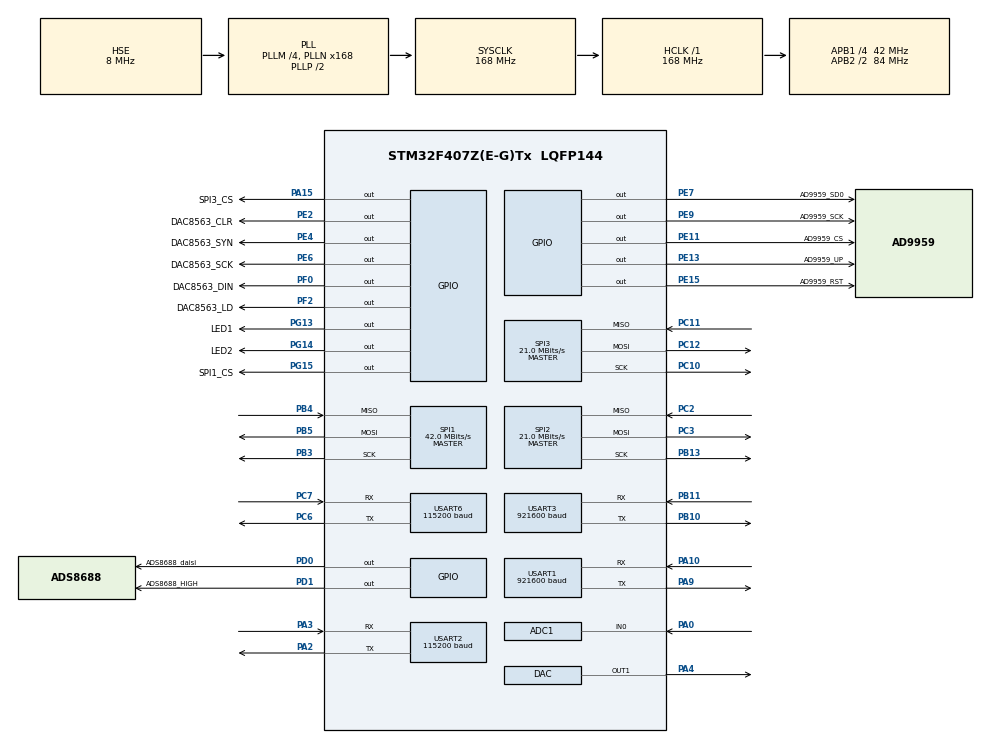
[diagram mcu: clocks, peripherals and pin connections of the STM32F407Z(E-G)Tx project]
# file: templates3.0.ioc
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PH0-OSC_IN.Signal=RCC_OSC_IN
SPI3.Direction=SPI_DIRECTION_2LINES
SPI3.VirtualType=VM_MASTER
SPI1.VirtualType=VM_MASTER
SPI2.VirtualType=VM_MASTER
PB10.Mode=Asynchronous
PC12.Signal=SPI3_MOSI
Dma.SPI3_RX.2.Direction=DMA_PERIPH_TO_MEMORY
PB13.Signal=SPI2_SCK
PG13.Signal=GPIO_Output
PE6.GPIO_Label=DAC8563_SCK
RCC.SYSCLKSource=RCC_SYSCLKSOURCE_PLLCLK
USART3.BaudRate=921600
PG15.GPIO_Label=SPI1_CS
SPI1.Direction=SPI_DIRECTION_2LINES
RCC.APB2TimFreq_Value=168000000
Dma.ADC1.0.Direction=DMA_PERIPH_TO_MEMORY
PC7.Signal=USART6_RX
SPI1.CalculateBaudRate=42.0 MBits/s
PC3.Signal=SPI2_MOSI
PD0.Signal=GPIO_Output
Dma.ADC1.0.MemDataAlignment=DMA_MDATAALIGN_HALFWORD
PB3.Mode=Full_Duplex_Master
PD1.GPIO_Label=ADS8688_HIGH
DAC.DAC_Trigger=DAC_TRIGGER_T6_TRGO
PD1.GPIO_Speed=GPIO_SPEED_FREQ_MEDIUM
PE9.Signal=GPIO_Output
Dma.ADC1.0.PeriphInc=DMA_PINC_DISABLE
SPI1.DataSize=SPI_DATASIZE_8BIT
PE4.GPIO_Label=DAC8563_SYN
SPI2.CalculateBaudRate=21.0 MBits/s
PE2.Signal=GPIO_Output
Dma.DAC1.1.Priority=DMA_PRIORITY_LOW
Mcu.Package=LQFP144
SPI2.Mode=SPI_MODE_MASTER
SPI3.Mode=SPI_MODE_MASTER
PA10.Signal=USART1_RX
PC11.Mode=Full_Duplex_Master
Dma.SPI3_RX.2.PeriphInc=DMA_PINC_DISABLE
RCC.APB2CLKDivider=RCC_HCLK_DIV2
RCC.APB1TimFreq_Value=84000000
Dma.ADC1.0.FIFOMode=DMA_FIFOMODE_DISABLE
PB13.Mode=Full_Duplex_Master
VP_TIM14_VS_ClockSourceINT.Mode=Enable_Timer
PE6.GPIO_Speed=GPIO_SPEED_FREQ_VERY_HIGH
Dma.SPI3_TX.3.Mode=DMA_NORMAL
Dma.ADC1.0.Instance=DMA2_Stream0
PE11.GPIO_Speed=GPIO_SPEED_FREQ_VERY_HIGH
PC6.Signal=USART6_TX
PC2.Signal=SPI2_MISO
PD1.Signal=GPIO_Output
PD1.GPIO_PuPd=GPIO_PULLUP
RCC.APB1CLKDivider=RCC_HCLK_DIV4
PG13.GPIO_Label=LED1
USART2.BaudRate=115200
PA0-WKUP.Signal=ADCx_IN0
PD0.GPIO_Speed=GPIO_SPEED_FREQ_MEDIUM
PA3.Mode=Asynchronous
PB11.Mode=Asynchronous
Dma.DAC1.1.Mode=DMA_CIRCULAR
PC6.Mode=Asynchronous
Dma.ADC1.0.Priority=DMA_PRIORITY_LOW
PA9.Signal=USART1_TX
PE9.GPIO_Label=AD9959_SCK
PB10.Signal=USART3_TX
PC12.Mode=Full_Duplex_Master
Dma.SPI3_TX.3.FIFOMode=DMA_FIFOMODE_DISABLE
NVIC.TIM3_IRQn=true\:3\:0\:true\:false\:true\:true\:false
VP_TIM13_VS_ClockSourceINT.Mode=Enable_Timer
Dma.SPI3_TX.3.Direction=DMA_MEMORY_TO_PERIPH
PE7.GPIO_Speed=GPIO_SPEED_FREQ_VERY_HIGH
PE15.Signal=GPIO_Output
SPI1.Mode=SPI_MODE_MASTER
ADC1.DMAContinuousRequests=ENABLE
PG14.GPIO_Label=LED2
Dma.DAC1.1.FIFOMode=DMA_FIFOMODE_DISABLE
TIM14.Prescaler=0
ADC1.SamplingTime-1\#ChannelRegularConversion=ADC_SAMPLETIME_3CYCLES
PA4.Signal=COMP_DAC1_group
PB5.Signal=SPI1_MOSI
ADC1.master=1
PE13.GPIO_Label=AD9959_UP
Dma.DAC1.1.Instance=DMA1_Stream5
USART1.VirtualMode=VM_ASYNC
ADC1.Rank-1\#ChannelRegularConversion=1
PD1.PinState=GPIO_PIN_SET
ProjectManager.HeapSize=0x200
NVIC.PriorityGroup=NVIC_PRIORITYGROUP_4
PE15.GPIO_Speed=GPIO_SPEED_FREQ_VERY_HIGH
PF0.GPIO_Label=DAC8563_DIN
Dma.SPI3_TX.3.Instance=DMA1_Stream7
Mcu.Family=STM32F4
NVIC.USART3_IRQn=true\:0\:0\:false\:false\:true\:true\:true
PC3.Mode=Full_Duplex_Master
RCC.CortexFreq_Value=168000000
Dma.SPI3_TX.3.MemDataAlignment=DMA_MDATAALIGN_HALFWORD
ADC1.ContinuousConvMode=ENABLE
PE11.GPIO_Label=AD9959_CS
USART1.BaudRate=921600
Dma.SPI3_RX.2.Instance=DMA1_Stream0
PC10.Signal=SPI3_SCK
Dma.DAC1.1.PeriphInc=DMA_PINC_DISABLE
PE2.GPIO_Speed=GPIO_SPEED_FREQ_VERY_HIGH
PD0.GPIO_Label=ADS8688_daisi
PE9.GPIO_Speed=GPIO_SPEED_FREQ_VERY_HIGH
PB11.Signal=USART3_RX
PF2.GPIO_Speed=GPIO_SPEED_FREQ_VERY_HIGH
PG15.Signal=GPIO_Output
Dma.SPI3_RX.2.PeriphDataAlignment=DMA_PDATAALIGN_HALFWORD
ProjectManager.StackSize=0x400
VP_TIM7_VS_ClockSourceINT.Mode=Enable_Timer
PA15.GPIO_Label=SPI3_CS
PG14.PinState=GPIO_PIN_SET
SPI1.CLKPolarity=SPI_POLARITY_LOW
RCC.HCLKFreq_Value=168000000
TIM3.Period=5249
TIM7.Period=9999
RCC.AHBFreq_Value=168000000
PH0-OSC_IN.Mode=HSE-External-Oscillator
SPI3.DataSize=SPI_DATASIZE_16BIT
RCC.HSE_VALUE=8000000
Dma.SPI3_TX.3.PeriphInc=DMA_PINC_DISABLE
Dma.SPI3_TX.3.Priority=DMA_PRIORITY_VERY_HIGH
PB4.Mode=Full_Duplex_Master
PE13.Signal=GPIO_Output
PD0.PinState=GPIO_PIN_SET
PE4.GPIO_Speed=GPIO_SPEED_FREQ_VERY_HIGH
PB5.Mode=Full_Duplex_Master
Dma.DAC1.1.PeriphDataAlignment=DMA_PDATAALIGN_HALFWORD
SH.ADCx_IN0.0=ADC1_IN0,IN0
TIM6.Period=9
PE4.Signal=GPIO_Output
Dma.SPI3_RX.2.FIFOMode=DMA_FIFOMODE_DISABLE
NVIC.DMA1_Stream7_IRQn=true\:4\:0\:true\:false\:true\:true\:true
Dma.DAC1.1.Direction=DMA_MEMORY_TO_PERIPH
PH1-OSC_OUT.Mode=HSE-External-Oscillator
USART2.VirtualMode=VM_ASYNC
USART6.VirtualMode=VM_ASYNC
PA15.Signal=GPIO_Output
USART6.BaudRate=115200
Dma.SPI3_RX.2.Priority=DMA_PRIORITY_VERY_HIGH
Dma.Request2=SPI3_RX
Dma.Request1=DAC1
Dma.Request3=SPI3_TX
NVIC.DMA1_Stream0_IRQn=true\:4\:0\:true\:false\:true\:true\:true
PG13.GPIO_Speed=GPIO_SPEED_FREQ_HIGH
SPI2.Direction=SPI_DIRECTION_2LINES
PF0.Signal=GPIO_Output
PE7.Signal=GPIO_Output
SPI3.CRCCalculation=SPI_CRCCALCULATION_DISABLE
Dma.Request0=ADC1
SPI1.BaudRatePrescaler=SPI_BAUDRATEPRESCALER_2
Dma.DAC1.1.MemDataAlignment=DMA_MDATAALIGN_HALFWORD
PE2.GPIO_Label=DAC8563_CLR
NVIC.TIM7_IRQn=true\:2\:0\:true\:false\:true\:true\:false
VP_TIM3_VS_ClockSourceINT.Mode=Internal
PB4.Signal=SPI1_MISO
PA3.Signal=USART2_RX
Dma.SPI3_TX.3.MemInc=DMA_MINC_ENABLE
RCC.PLLSourceVirtual=RCC_PLLSOURCE_HSE
SH.COMP_DAC1_group.0=DAC_OUT1,DAC_OUT1
PA10.Mode=Asynchronous
PC11.Signal=SPI3_MISO
TIM6.Prescaler=83
PC10.Mode=Full_Duplex_Master
VP_TIM6_VS_ClockSourceINT.Mode=Enable_Timer
PC2.Mode=Full_Duplex_Master
NVIC.USART2_IRQn=true\:0\:0\:false\:false\:true\:true\:true
NVIC.USART6_IRQn=true\:1\:0\:true\:false\:true\:true\:true
PF0.GPIO_Speed=GPIO_SPEED_FREQ_VERY_HIGH
Dma.DAC1.1.MemInc=DMA_MINC_ENABLE
Dma.ADC1.0.PeriphDataAlignment=DMA_PDATAALIGN_HALFWORD
PA9.Mode=Asynchronous
PE15.GPIO_Label=AD9959_RST
ProjectManager.TargetToolchain=STM32CubeIDE
Dma.ADC1.0.Mode=DMA_CIRCULAR
ADC1.Channel-1\#ChannelRegularConversion=ADC_CHANNEL_0
PF2.Signal=GPIO_Output
PE11.Signal=GPIO_Output
RCC.LSE_VALUE=32768
PG14.Signal=GPIO_Output
TIM7.Prescaler=8399
board=custom
SPI3.CLKPhase=SPI_PHASE_2EDGE
RCC.VCOOutputFreq_Value=336000000
PA15.PinState=GPIO_PIN_SET
RCC.APB2Freq_Value=84000000
SPI3.CalculateBaudRate=21.0 MBits/s
VP_TIM2_VS_ClockSourceINT.Mode=Internal
SPI3.BaudRatePrescaler=SPI_BAUDRATEPRESCALER_2
Dma.SPI3_TX.3.PeriphDataAlignment=DMA_PDATAALIGN_HALFWORD
TIM6.TIM_MasterOutputTrigger=TIM_TRGO_UPDATE
PH1-OSC_OUT.Signal=RCC_OSC_OUT
PE6.Signal=GPIO_Output
Dma.SPI3_RX.2.Mode=DMA_NORMAL
Mcu.Name=STM32F407Z(E-G)Tx
PE7.GPIO_Label=AD9959_SD0
PA2.Signal=USART2_TX
RCC.48MHZClocksFreq_Value=84000000
PB3.Signal=SPI1_SCK
RCC.SYSCLKFreq_VALUE=168000000
USART3.VirtualMode=VM_ASYNC
Dma.SPI3_RX.2.MemInc=DMA_MINC_ENABLE
PA15.GPIO_Speed=GPIO_SPEED_FREQ_VERY_HIGH
Dma.ADC1.0.MemInc=DMA_MINC_ENABLE
RCC.HSI_VALUE=16000000
ADC1.NbrOfConversionFlag=1
RCC.PLLM=4
RCC.PLLN=168
PE13.GPIO_Speed=GPIO_SPEED_FREQ_VERY_HIGH
PA2.Mode=Asynchronous
PC7.Mode=Asynchronous
Dma.SPI3_RX.2.MemDataAlignment=DMA_MDATAALIGN_HALFWORD
RCC.APB1Freq_Value=42000000
PG14.GPIO_Speed=GPIO_SPEED_FREQ_HIGH
PF2.GPIO_Label=DAC8563_LD

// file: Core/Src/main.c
/* USER CODE BEGIN Header */
/**
  ******************************************************************************
  * @file           : main.c
  * @brief          : Main program body
  ******************************************************************************
  * @attention
  *
  * <h2><center>&copy; Copyright (c) 2021 STMicroelectronics.
  * All rights reserved.</center></h2>
  *
  * This software component is licensed by ST under BSD 3-Clause license,
  * the "License"; You may not use this file except in compliance with the
  * License. You may obtain a copy of the License at:
  *                        opensource.org/licenses/BSD-3-Clause
  *
  ******************************************************************************
  */
/* USER CODE END Header */
#include "main.h"

ADC_HandleTypeDef hadc1;
DMA_HandleTypeDef hdma_adc1;

DAC_HandleTypeDef hdac;
DMA_HandleTypeDef hdma_dac1;

SPI_HandleTypeDef hspi1;
SPI_HandleTypeDef hspi2;
SPI_HandleTypeDef hspi3;
DMA_HandleTypeDef hdma_spi3_rx;
DMA_HandleTypeDef hdma_spi3_tx;

TIM_HandleTypeDef htim2;
TIM_HandleTypeDef htim3;
TIM_HandleTypeDef htim6;
TIM_HandleTypeDef htim7;
TIM_HandleTypeDef htim13;
TIM_HandleTypeDef htim14;

UART_HandleTypeDef huart1;
UART_HandleTypeDef huart2;
UART_HandleTypeDef huart3;
UART_HandleTypeDef huart6;

void SystemClock_Config(void);
static void MX_GPIO_Init(void);
static void MX_DMA_Init(void);
static void MX_SPI3_Init(void);
static void MX_TIM7_Init(void);
static void MX_USART1_UART_Init(void);
static void MX_USART2_UART_Init(void);
static void MX_USART3_UART_Init(void);
static void MX_USART6_UART_Init(void);
static void MX_SPI1_Init(void);
static void MX_TIM3_Init(void);
static void MX_ADC1_Init(void);
static void MX_DAC_Init(void);
static void MX_TIM6_Init(void);
static void MX_TIM2_Init(void);
static void MX_TIM14_Init(void);
static void MX_SPI2_Init(void);
static void MX_TIM13_Init(void);

int main(void)
{

  /* MCU Configuration--------------------------------------------------------*/

  /* Reset of all peripherals, Initializes the Flash interface and the Systick. */
  HAL_Init();

  /* Configure the system clock */
  SystemClock_Config();

  /* Initialize all configured peripherals */
  MX_GPIO_Init();
  MX_DMA_Init();
  MX_SPI3_Init();
  MX_TIM7_Init();
  MX_USART1_UART_Init();
  MX_USART2_UART_Init();
  MX_USART3_UART_Init();
  MX_USART6_UART_Init();
  MX_SPI1_Init();
  MX_TIM3_Init();
  MX_ADC1_Init();
  MX_DAC_Init();
  MX_TIM6_Init();
  MX_TIM2_Init();
  MX_TIM14_Init();
  MX_SPI2_Init();
  MX_TIM13_Init();
  /* USER CODE BEGIN 2 */

  init_start();

  /* USER CODE END 2 */

  /* Infinite loop */
  /* USER CODE BEGIN WHILE */
  while (1)
  {
	  while_do();
    /* USER CODE END WHILE */

  }
}

void SystemClock_Config(void)
{
  RCC_OscInitTypeDef RCC_OscInitStruct = {0};
  RCC_ClkInitTypeDef RCC_ClkInitStruct = {0};

  /** Configure the main internal regulator output voltage
  */
  __HAL_RCC_PWR_CLK_ENABLE();
  __HAL_PWR_VOLTAGESCALING_CONFIG(PWR_REGULATOR_VOLTAGE_SCALE1);
  /** Initializes the RCC Oscillators according to the specified parameters
  * in the RCC_OscInitTypeDef structure.
  */
  RCC_OscInitStruct.OscillatorType = RCC_OSCILLATORTYPE_HSE;
  RCC_OscInitStruct.HSEState = RCC_HSE_ON;
  RCC_OscInitStruct.PLL.PLLState = RCC_PLL_ON;
  RCC_OscInitStruct.PLL.PLLSource = RCC_PLLSOURCE_HSE;
  RCC_OscInitStruct.PLL.PLLM = 4;
  RCC_OscInitStruct.PLL.PLLN = 168;
  RCC_OscInitStruct.PLL.PLLP = RCC_PLLP_DIV2;
  RCC_OscInitStruct.PLL.PLLQ = 4;
  if (HAL_RCC_OscConfig(&RCC_OscInitStruct) != HAL_OK)
  {
    Error_Handler();
  }
  /** Initializes the CPU, AHB and APB buses clocks
  */
  RCC_ClkInitStruct.ClockType = RCC_CLOCKTYPE_HCLK|RCC_CLOCKTYPE_SYSCLK
                              |RCC_CLOCKTYPE_PCLK1|RCC_CLOCKTYPE_PCLK2;
  RCC_ClkInitStruct.SYSCLKSource = RCC_SYSCLKSOURCE_PLLCLK;
  RCC_ClkInitStruct.AHBCLKDivider = RCC_SYSCLK_DIV1;
  RCC_ClkInitStruct.APB1CLKDivider = RCC_HCLK_DIV4;
  RCC_ClkInitStruct.APB2CLKDivider = RCC_HCLK_DIV2;

  if (HAL_RCC_ClockConfig(&RCC_ClkInitStruct, FLASH_LATENCY_5) != HAL_OK)
  {
    Error_Handler();
  }
}

static void MX_ADC1_Init(void)
{

  ADC_ChannelConfTypeDef sConfig = {0};

  /** Configure the global features of the ADC (Clock, Resolution, Data Alignment and number of conversion)
  */
  hadc1.Instance = ADC1;
  hadc1.Init.ClockPrescaler = ADC_CLOCK_SYNC_PCLK_DIV4;
  hadc1.Init.Resolution = ADC_RESOLUTION_12B;
  hadc1.Init.ScanConvMode = DISABLE;
  hadc1.Init.ContinuousConvMode = ENABLE;
  hadc1.Init.DiscontinuousConvMode = DISABLE;
  hadc1.Init.ExternalTrigConvEdge = ADC_EXTERNALTRIGCONVEDGE_NONE;
  hadc1.Init.ExternalTrigConv = ADC_SOFTWARE_START;
  hadc1.Init.DataAlign = ADC_DATAALIGN_RIGHT;
  hadc1.Init.NbrOfConversion = 1;
  hadc1.Init.DMAContinuousRequests = ENABLE;
  hadc1.Init.EOCSelection = ADC_EOC_SINGLE_CONV;
  if (HAL_ADC_Init(&hadc1) != HAL_OK)
  {
    Error_Handler();
  }
  /** Configure for the selected ADC regular channel its corresponding rank in the sequencer and its sample time.
  */
  sConfig.Channel = ADC_CHANNEL_0;
  sConfig.Rank = 1;
  sConfig.SamplingTime = ADC_SAMPLETIME_3CYCLES;
  if (HAL_ADC_ConfigChannel(&hadc1, &sConfig) != HAL_OK)
  {
    Error_Handler();
  }

}

static void MX_DAC_Init(void)
{

  DAC_ChannelConfTypeDef sConfig = {0};

  /** DAC Initialization
  */
  hdac.Instance = DAC;
  if (HAL_DAC_Init(&hdac) != HAL_OK)
  {
    Error_Handler();
  }
  /** DAC channel OUT1 config
  */
  sConfig.DAC_Trigger = DAC_TRIGGER_T6_TRGO;
  sConfig.DAC_OutputBuffer = DAC_OUTPUTBUFFER_ENABLE;
  if (HAL_DAC_ConfigChannel(&hdac, &sConfig, DAC_CHANNEL_1) != HAL_OK)
  {
    Error_Handler();
  }

}

static void MX_SPI1_Init(void)
{

  /* SPI1 parameter configuration*/
  hspi1.Instance = SPI1;
  hspi1.Init.Mode = SPI_MODE_MASTER;
  hspi1.Init.Direction = SPI_DIRECTION_2LINES;
  hspi1.Init.DataSize = SPI_DATASIZE_8BIT;
  hspi1.Init.CLKPolarity = SPI_POLARITY_LOW;
  hspi1.Init.CLKPhase = SPI_PHASE_1EDGE;
  hspi1.Init.NSS = SPI_NSS_SOFT;
  hspi1.Init.BaudRatePrescaler = SPI_BAUDRATEPRESCALER_2;
  hspi1.Init.FirstBit = SPI_FIRSTBIT_MSB;
  hspi1.Init.TIMode = SPI_TIMODE_DISABLE;
  hspi1.Init.CRCCalculation = SPI_CRCCALCULATION_DISABLE;
  hspi1.Init.CRCPolynomial = 10;
  if (HAL_SPI_Init(&hspi1) != HAL_OK)
  {
    Error_Handler();
  }

}

static void MX_SPI2_Init(void)
{

  /* SPI2 parameter configuration*/
  hspi2.Instance = SPI2;
  hspi2.Init.Mode = SPI_MODE_MASTER;
  hspi2.Init.Direction = SPI_DIRECTION_2LINES;
  hspi2.Init.DataSize = SPI_DATASIZE_8BIT;
  hspi2.Init.CLKPolarity = SPI_POLARITY_LOW;
  hspi2.Init.CLKPhase = SPI_PHASE_1EDGE;
  hspi2.Init.NSS = SPI_NSS_SOFT;
  hspi2.Init.BaudRatePrescaler = SPI_BAUDRATEPRESCALER_2;
  hspi2.Init.FirstBit = SPI_FIRSTBIT_MSB;
  hspi2.Init.TIMode = SPI_TIMODE_DISABLE;
  hspi2.Init.CRCCalculation = SPI_CRCCALCULATION_DISABLE;
  hspi2.Init.CRCPolynomial = 10;
  if (HAL_SPI_Init(&hspi2) != HAL_OK)
  {
    Error_Handler();
  }

}

static void MX_SPI3_Init(void)
{

  /* SPI3 parameter configuration*/
  hspi3.Instance = SPI3;
  hspi3.Init.Mode = SPI_MODE_MASTER;
  hspi3.Init.Direction = SPI_DIRECTION_2LINES;
  hspi3.Init.DataSize = SPI_DATASIZE_16BIT;
  hspi3.Init.CLKPolarity = SPI_POLARITY_LOW;
  hspi3.Init.CLKPhase = SPI_PHASE_2EDGE;
  hspi3.Init.NSS = SPI_NSS_SOFT;
  hspi3.Init.BaudRatePrescaler = SPI_BAUDRATEPRESCALER_2;
  hspi3.Init.FirstBit = SPI_FIRSTBIT_MSB;
  hspi3.Init.TIMode = SPI_TIMODE_DISABLE;
  hspi3.Init.CRCCalculation = SPI_CRCCALCULATION_DISABLE;
  hspi3.Init.CRCPolynomial = 10;
  if (HAL_SPI_Init(&hspi3) != HAL_OK)
  {
    Error_Handler();
  }

}

static void MX_TIM2_Init(void)
{

  TIM_ClockConfigTypeDef sClockSourceConfig = {0};
  TIM_MasterConfigTypeDef sMasterConfig = {0};

  htim2.Instance = TIM2;
  htim2.Init.Prescaler = 0;
  htim2.Init.CounterMode = TIM_COUNTERMODE_UP;
  htim2.Init.Period = 4294967295;
  htim2.Init.ClockDivision = TIM_CLOCKDIVISION_DIV1;
  htim2.Init.AutoReloadPreload = TIM_AUTORELOAD_PRELOAD_DISABLE;
  if (HAL_TIM_Base_Init(&htim2) != HAL_OK)
  {
    Error_Handler();
  }
  sClockSourceConfig.ClockSource = TIM_CLOCKSOURCE_INTERNAL;
  if (HAL_TIM_ConfigClockSource(&htim2, &sClockSourceConfig) != HAL_OK)
  {
    Error_Handler();
  }
  sMasterConfig.MasterOutputTrigger = TIM_TRGO_RESET;
  sMasterConfig.MasterSlaveMode = TIM_MASTERSLAVEMODE_DISABLE;
  if (HAL_TIMEx_MasterConfigSynchronization(&htim2, &sMasterConfig) != HAL_OK)
  {
    Error_Handler();
  }

}

static void MX_TIM3_Init(void)
{

  TIM_ClockConfigTypeDef sClockSourceConfig = {0};
  TIM_MasterConfigTypeDef sMasterConfig = {0};

  htim3.Instance = TIM3;
  htim3.Init.Prescaler = 0;
  htim3.Init.CounterMode = TIM_COUNTERMODE_UP;
  htim3.Init.Period = 5249;
  htim3.Init.ClockDivision = TIM_CLOCKDIVISION_DIV1;
  htim3.Init.AutoReloadPreload = TIM_AUTORELOAD_PRELOAD_DISABLE;
  if (HAL_TIM_Base_Init(&htim3) != HAL_OK)
  {
    Error_Handler();
  }
  sClockSourceConfig.ClockSource = TIM_CLOCKSOURCE_INTERNAL;
  if (HAL_TIM_ConfigClockSource(&htim3, &sClockSourceConfig) != HAL_OK)
  {
    Error_Handler();
  }
  sMasterConfig.MasterOutputTrigger = TIM_TRGO_RESET;
  sMasterConfig.MasterSlaveMode = TIM_MASTERSLAVEMODE_DISABLE;
  if (HAL_TIMEx_MasterConfigSynchronization(&htim3, &sMasterConfig) != HAL_OK)
  {
    Error_Handler();
  }

}

static void MX_TIM6_Init(void)
{

  TIM_MasterConfigTypeDef sMasterConfig = {0};

  htim6.Instance = TIM6;
  htim6.Init.Prescaler = 83;
  htim6.Init.CounterMode = TIM_COUNTERMODE_UP;
  htim6.Init.Period = 9;
  htim6.Init.AutoReloadPreload = TIM_AUTORELOAD_PRELOAD_DISABLE;
  if (HAL_TIM_Base_Init(&htim6) != HAL_OK)
  {
    Error_Handler();
  }
  sMasterConfig.MasterOutputTrigger = TIM_TRGO_UPDATE;
  sMasterConfig.MasterSlaveMode = TIM_MASTERSLAVEMODE_DISABLE;
  if (HAL_TIMEx_MasterConfigSynchronization(&htim6, &sMasterConfig) != HAL_OK)
  {
    Error_Handler();
  }

}

static void MX_TIM7_Init(void)
{

  TIM_MasterConfigTypeDef sMasterConfig = {0};

  htim7.Instance = TIM7;
  htim7.Init.Prescaler = 8399;
  htim7.Init.CounterMode = TIM_COUNTERMODE_UP;
  htim7.Init.Period = 9999;
  htim7.Init.AutoReloadPreload = TIM_AUTORELOAD_PRELOAD_DISABLE;
  if (HAL_TIM_Base_Init(&htim7) != HAL_OK)
  {
    Error_Handler();
  }
  sMasterConfig.MasterOutputTrigger = TIM_TRGO_RESET;
  sMasterConfig.MasterSlaveMode = TIM_MASTERSLAVEMODE_DISABLE;
  if (HAL_TIMEx_MasterConfigSynchronization(&htim7, &sMasterConfig) != HAL_OK)
  {
    Error_Handler();
  }

}

static void MX_TIM13_Init(void)
{

  htim13.Instance = TIM13;
  htim13.Init.Prescaler = 0;
  htim13.Init.CounterMode = TIM_COUNTERMODE_UP;
  htim13.Init.Period = 65535;
  htim13.Init.ClockDivision = TIM_CLOCKDIVISION_DIV1;
  htim13.Init.AutoReloadPreload = TIM_AUTORELOAD_PRELOAD_DISABLE;
  if (HAL_TIM_Base_Init(&htim13) != HAL_OK)
  {
    Error_Handler();
  }

}

static void MX_TIM14_Init(void)
{

  htim14.Instance = TIM14;
  htim14.Init.Prescaler = 0;
  htim14.Init.CounterMode = TIM_COUNTERMODE_UP;
  htim14.Init.Period = 65535;
  htim14.Init.ClockDivision = TIM_CLOCKDIVISION_DIV1;
  htim14.Init.AutoReloadPreload = TIM_AUTORELOAD_PRELOAD_DISABLE;
  if (HAL_TIM_Base_Init(&htim14) != HAL_OK)
  {
    Error_Handler();
  }

}

static void MX_USART1_UART_Init(void)
{

  huart1.Instance = USART1;
  huart1.Init.BaudRate = 921600;
  huart1.Init.WordLength = UART_WORDLENGTH_8B;
  huart1.Init.StopBits = UART_STOPBITS_1;
  huart1.Init.Parity = UART_PARITY_NONE;
  huart1.Init.Mode = UART_MODE_TX_RX;
  huart1.Init.HwFlowCtl = UART_HWCONTROL_NONE;
  huart1.Init.OverSampling = UART_OVERSAMPLING_16;
  if (HAL_UART_Init(&huart1) != HAL_OK)
  {
    Error_Handler();
  }

}

static void MX_USART2_UART_Init(void)
{

  huart2.Instance = USART2;
  huart2.Init.BaudRate = 115200;
  huart2.Init.WordLength = UART_WORDLENGTH_8B;
  huart2.Init.StopBits = UART_STOPBITS_1;
  huart2.Init.Parity = UART_PARITY_NONE;
  huart2.Init.Mode = UART_MODE_TX_RX;
  huart2.Init.HwFlowCtl = UART_HWCONTROL_NONE;
  huart2.Init.OverSampling = UART_OVERSAMPLING_16;
  if (HAL_UART_Init(&huart2) != HAL_OK)
  {
    Error_Handler();
  }

}

static void MX_USART3_UART_Init(void)
{

  huart3.Instance = USART3;
  huart3.Init.BaudRate = 921600;
  huart3.Init.WordLength = UART_WORDLENGTH_8B;
  huart3.Init.StopBits = UART_STOPBITS_1;
  huart3.Init.Parity = UART_PARITY_NONE;
  huart3.Init.Mode = UART_MODE_TX_RX;
  huart3.Init.HwFlowCtl = UART_HWCONTROL_NONE;
  huart3.Init.OverSampling = UART_OVERSAMPLING_16;
  if (HAL_UART_Init(&huart3) != HAL_OK)
  {
    Error_Handler();
  }

}

static void MX_USART6_UART_Init(void)
{

  huart6.Instance = USART6;
  huart6.Init.BaudRate = 115200;
  huart6.Init.WordLength = UART_WORDLENGTH_8B;
  huart6.Init.StopBits = UART_STOPBITS_1;
  huart6.Init.Parity = UART_PARITY_NONE;
  huart6.Init.Mode = UART_MODE_TX_RX;
  huart6.Init.HwFlowCtl = UART_HWCONTROL_NONE;
  huart6.Init.OverSampling = UART_OVERSAMPLING_16;
  if (HAL_UART_Init(&huart6) != HAL_OK)
  {
    Error_Handler();
  }

}

static void MX_DMA_Init(void)
{

  /* DMA controller clock enable */
  __HAL_RCC_DMA2_CLK_ENABLE();
  __HAL_RCC_DMA1_CLK_ENABLE();

  /* DMA interrupt init */
  /* DMA1_Stream0_IRQn interrupt configuration */
  HAL_NVIC_SetPriority(DMA1_Stream0_IRQn, 4, 0);
  HAL_NVIC_EnableIRQ(DMA1_Stream0_IRQn);
  /* DMA1_Stream7_IRQn interrupt configuration */
  HAL_NVIC_SetPriority(DMA1_Stream7_IRQn, 4, 0);
  HAL_NVIC_EnableIRQ(DMA1_Stream7_IRQn);

}

static void MX_GPIO_Init(void)
{
  GPIO_InitTypeDef GPIO_InitStruct = {0};

  /* GPIO Ports Clock Enable */
  __HAL_RCC_GPIOE_CLK_ENABLE();
  __HAL_RCC_GPIOF_CLK_ENABLE();
  __HAL_RCC_GPIOH_CLK_ENABLE();
  __HAL_RCC_GPIOC_CLK_ENABLE();
  __HAL_RCC_GPIOA_CLK_ENABLE();
  __HAL_RCC_GPIOB_CLK_ENABLE();
  __HAL_RCC_GPIOD_CLK_ENABLE();
  __HAL_RCC_GPIOG_CLK_ENABLE();

  /*Configure GPIO pin Output Level */
  HAL_GPIO_WritePin(GPIOE, DAC8563_CLR_Pin|DAC8563_SYN_Pin|DAC8563_SCK_Pin|AD9959_SD0_Pin
                          |AD9959_SCK_Pin|AD9959_CS_Pin|AD9959_UP_Pin|AD9959_RST_Pin, GPIO_PIN_RESET);

  /*Configure GPIO pin Output Level */
  HAL_GPIO_WritePin(GPIOF, DAC8563_DIN_Pin|DAC8563_LD_Pin, GPIO_PIN_RESET);

  /*Configure GPIO pin Output Level */
  HAL_GPIO_WritePin(SPI3_CS_GPIO_Port, SPI3_CS_Pin, GPIO_PIN_SET);

  /*Configure GPIO pin Output Level */
  HAL_GPIO_WritePin(GPIOD, ADS8688_daisi_Pin|ADS8688_HIGH_Pin, GPIO_PIN_SET);

  /*Configure GPIO pin Output Level */
  HAL_GPIO_WritePin(GPIOG, LED1_Pin|SPI1_CS_Pin, GPIO_PIN_RESET);

  /*Configure GPIO pin Output Level */
  HAL_GPIO_WritePin(LED2_GPIO_Port, LED2_Pin, GPIO_PIN_SET);

  /*Configure GPIO pins : DAC8563_CLR_Pin DAC8563_SYN_Pin DAC8563_SCK_Pin AD9959_SD0_Pin
                           AD9959_SCK_Pin AD9959_CS_Pin AD9959_UP_Pin AD9959_RST_Pin */
  GPIO_InitStruct.Pin = DAC8563_CLR_Pin|DAC8563_SYN_Pin|DAC8563_SCK_Pin|AD9959_SD0_Pin
                          |AD9959_SCK_Pin|AD9959_CS_Pin|AD9959_UP_Pin|AD9959_RST_Pin;
  GPIO_InitStruct.Mode = GPIO_MODE_OUTPUT_PP;
  GPIO_InitStruct.Pull = GPIO_NOPULL;
  GPIO_InitStruct.Speed = GPIO_SPEED_FREQ_VERY_HIGH;
  HAL_GPIO_Init(GPIOE, &GPIO_InitStruct);

  /*Configure GPIO pins : DAC8563_DIN_Pin DAC8563_LD_Pin */
  GPIO_InitStruct.Pin = DAC8563_DIN_Pin|DAC8563_LD_Pin;
  GPIO_InitStruct.Mode = GPIO_MODE_OUTPUT_PP;
  GPIO_InitStruct.Pull = GPIO_NOPULL;
  GPIO_InitStruct.Speed = GPIO_SPEED_FREQ_VERY_HIGH;
  HAL_GPIO_Init(GPIOF, &GPIO_InitStruct);

  /*Configure GPIO pin : SPI3_CS_Pin */
  GPIO_InitStruct.Pin = SPI3_CS_Pin;
  GPIO_InitStruct.Mode = GPIO_MODE_OUTPUT_PP;
  GPIO_InitStruct.Pull = GPIO_NOPULL;
  GPIO_InitStruct.Speed = GPIO_SPEED_FREQ_VERY_HIGH;
  HAL_GPIO_Init(SPI3_CS_GPIO_Port, &GPIO_InitStruct);

  /*Configure GPIO pin : ADS8688_daisi_Pin */
  GPIO_InitStruct.Pin = ADS8688_daisi_Pin;
  GPIO_InitStruct.Mode = GPIO_MODE_OUTPUT_PP;
  GPIO_InitStruct.Pull = GPIO_NOPULL;
  GPIO_InitStruct.Speed = GPIO_SPEED_FREQ_MEDIUM;
  HAL_GPIO_Init(ADS8688_daisi_GPIO_Port, &GPIO_InitStruct);

  /*Configure GPIO pin : ADS8688_HIGH_Pin */
  GPIO_InitStruct.Pin = ADS8688_HIGH_Pin;
  GPIO_InitStruct.Mode = GPIO_MODE_OUTPUT_PP;
  GPIO_InitStruct.Pull = GPIO_PULLUP;
  GPIO_InitStruct.Speed = GPIO_SPEED_FREQ_MEDIUM;
  HAL_GPIO_Init(ADS8688_HIGH_GPIO_Port, &GPIO_InitStruct);

  /*Configure GPIO pins : LED1_Pin LED2_Pin */
  GPIO_InitStruct.Pin = LED1_Pin|LED2_Pin;
  GPIO_InitStruct.Mode = GPIO_MODE_OUTPUT_PP;
  GPIO_InitStruct.Pull = GPIO_NOPULL;
  GPIO_InitStruct.Speed = GPIO_SPEED_FREQ_HIGH;
  HAL_GPIO_Init(GPIOG, &GPIO_InitStruct);

  /*Configure GPIO pin : SPI1_CS_Pin */
  GPIO_InitStruct.Pin = SPI1_CS_Pin;
  GPIO_InitStruct.Mode = GPIO_MODE_OUTPUT_PP;
  GPIO_InitStruct.Pull = GPIO_NOPULL;
  GPIO_InitStruct.Speed = GPIO_SPEED_FREQ_LOW;
  HAL_GPIO_Init(SPI1_CS_GPIO_Port, &GPIO_InitStruct);

}

void Error_Handler(void)
{
  __disable_irq();
  while (1)
  {
  }
}

/************************ (C) COPYRIGHT STMicroelectronics *****END OF FILE****/
